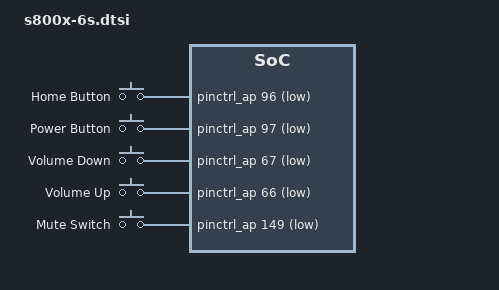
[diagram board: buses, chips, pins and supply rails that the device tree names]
// SPDX-License-Identifier: GPL-2.0+ OR MIT
/*
 * Apple iPhone 6s / 6S Plus common device tree
 *
 * Copyright (c) 2022, Konrad Dybcio <konradybcio@kernel.org>
 */

#include "s800-0-3-common.dtsi"
#include <dt-bindings/input/input.h>

/ {
	chassis-type = "handset";

	gpio-keys {
		compatible = "gpio-keys";

		button-home {
			label = "Home Button";
			gpios = <&pinctrl_ap 96 GPIO_ACTIVE_LOW>;
			linux,code = <KEY_HOMEPAGE>;
			wakeup-source;
		};

		button-power {
			label = "Power Button";
			gpios = <&pinctrl_ap 97 GPIO_ACTIVE_LOW>;
			linux,code = <KEY_POWER>;
			wakeup-source;
		};

		button-voldown {
			label = "Volume Down";
			gpios = <&pinctrl_ap 67 GPIO_ACTIVE_LOW>;
			linux,code = <KEY_VOLUMEDOWN>;
		};

		button-volup {
			label = "Volume Up";
			gpios = <&pinctrl_ap 66 GPIO_ACTIVE_LOW>;
			linux,code = <KEY_VOLUMEUP>;
		};

		switch-mute {
			label = "Mute Switch";
			gpios = <&pinctrl_ap 149 GPIO_ACTIVE_LOW>;
			linux,code = <KEY_MUTE>;
		};
	};
};
